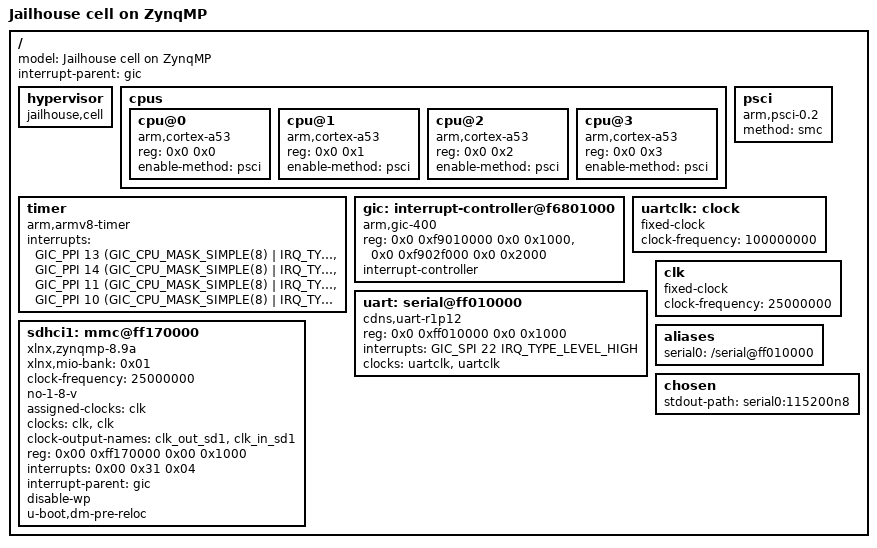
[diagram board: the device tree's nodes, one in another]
/*
 * Jailhouse, a Linux-based partitioning hypervisor
 *
 * Device tree for Linux inmate test on ZynqMP ZCU102 and Ultra96 boards,
 * corresponds to configs/arm64/zynqmp-zcu102-linux-demo.c and
 * configs/arm64/ultra96-linux-demo.c.
 *
 * Copyright (c) Siemens AG, 2016-2019
 *
 * Authors:
 *  Jan Kiszka <jan.kiszka@siemens.com>
 *
 * This work is licensed under the terms of the GNU GPL, version 2.  See
 * the COPYING file in the top-level directory.
 */

#include <dt-bindings/interrupt-controller/arm-gic.h>

/dts-v1/;

/ {
	model = "Jailhouse cell on ZynqMP";

	#address-cells = <2>;
	#size-cells = <2>;

	interrupt-parent = <&gic>;

	hypervisor {
		compatible = "jailhouse,cell";
	};

	cpus {
		#address-cells = <2>;
		#size-cells = <0>;

		cpu@0 {
			compatible = "arm,cortex-a53", "arm,armv8";
			device_type = "cpu";
			reg = <0x0 0x0>;
			enable-method = "psci";
		};
		cpu@1 {
			compatible = "arm,cortex-a53", "arm,armv8";
			device_type = "cpu";
			reg = <0x0 0x1>;
			enable-method = "psci";
		};

		cpu@2 {
			compatible = "arm,cortex-a53", "arm,armv8";
			device_type = "cpu";
			reg = <0x0 0x2>;
			enable-method = "psci";
		};

		cpu@3 {
			compatible = "arm,cortex-a53", "arm,armv8";
			device_type = "cpu";
			reg = <0x0 0x3>;
			enable-method = "psci";
		};

	};

	psci {
		compatible = "arm,psci-0.2";
		method = "smc";
	};

	timer {
		compatible = "arm,armv8-timer";
		interrupts = <GIC_PPI 13 (GIC_CPU_MASK_SIMPLE(8) | IRQ_TYPE_LEVEL_LOW)>,
			     <GIC_PPI 14
				(GIC_CPU_MASK_SIMPLE(8) | IRQ_TYPE_LEVEL_LOW)>,
			     <GIC_PPI 11
				(GIC_CPU_MASK_SIMPLE(8) | IRQ_TYPE_LEVEL_LOW)>,
			     <GIC_PPI 10
				(GIC_CPU_MASK_SIMPLE(8) | IRQ_TYPE_LEVEL_LOW)>;
	};

	gic: interrupt-controller@f6801000 {
		compatible = "arm,gic-400";
		reg = <0x0 0xf9010000 0x0 0x1000>,
		      <0x0 0xf902f000 0x0 0x2000>;
		interrupt-controller;
		#interrupt-cells = <3>;
	};

	uartclk: clock {
		compatible = "fixed-clock";
		#clock-cells = <0>;
		clock-frequency = <100000000>;
	};

	uart: serial@ff010000 { //UART for controlling the VM is controlled
		compatible = "cdns,uart-r1p12", "xlnx,xuartps";
		reg = <0x0 0xff010000 0x0 0x1000>;
		interrupts = <GIC_SPI 22 IRQ_TYPE_LEVEL_HIGH>;
		clocks = <&uartclk>, <&uartclk>;
		clock-names = "uart_clk", "pclk";
	};
	
	clk: clk {
		#clock-cells = <0x0>;
		clock-frequency = <25000000>;
		compatible = "fixed-clock";
	};
	//SDHC with which the attack is achieved
	sdhci1: mmc@ff170000 { 
		xlnx,mio-bank = <0x01>;
		clock-frequency = <25000000>;
		no-1-8-v;
		assigned-clocks = <&clk>;
		clocks = <&clk &clk>;
		clock-output-names = "clk_out_sd1", "clk_in_sd1";
		#clock-cells = <0x01>;
		clock-names = "clk_xin", "clk_ahb";
		reg = <0x00 0xff170000 0x00 0x1000>;
		interrupts = <0x00 0x31 0x04>;
		interrupt-parent = <&gic>;
		status = "okay";
		disable-wp;
		compatible = "xlnx,zynqmp-8.9a", "arasan,sdhci-8.9a";
		u-boot,dm-pre-reloc;
	};
	
	aliases {
		serial0 = "/serial@ff010000";
	};
	chosen {
		stdout-path = "serial0:115200n8";
	};



};
